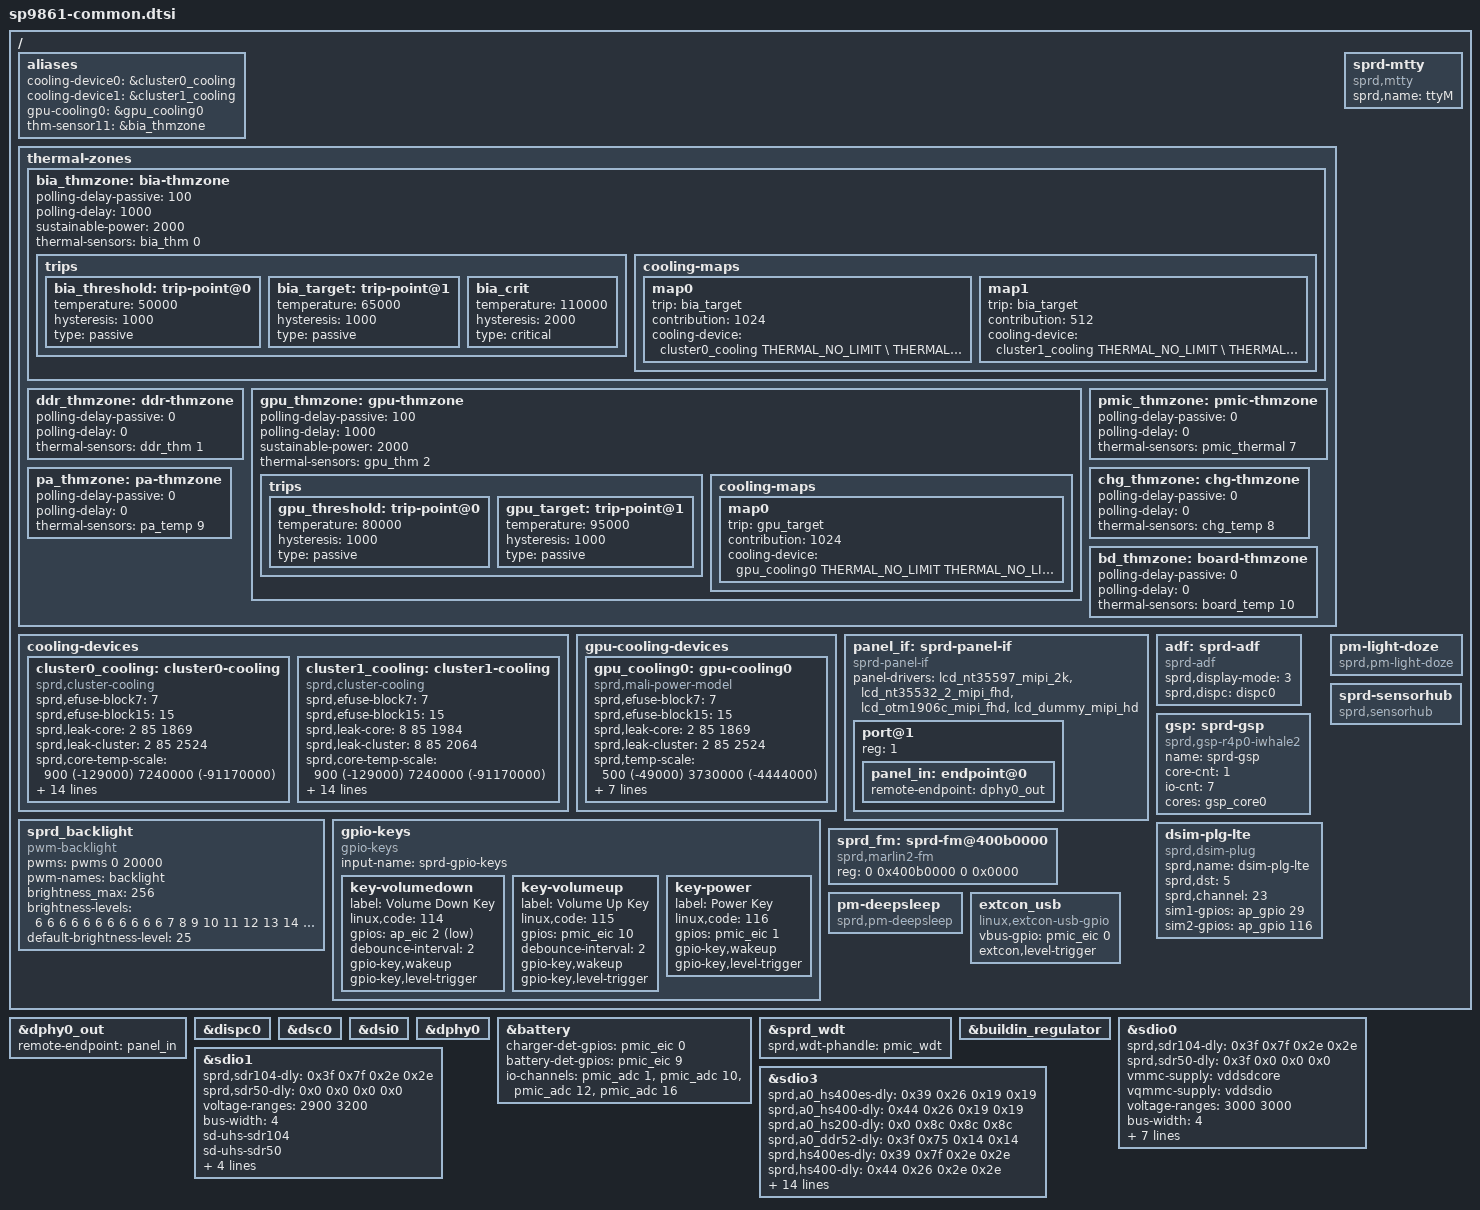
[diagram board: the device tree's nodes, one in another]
/*
 * Spreadtrum SP98x0 board common DTS file
 *
 * Copyright (C) 2016, Spreadtrum Communications Inc.
 *
 * This file is licensed under a dual GPLv2 or X11 license.
 */

#include "lcd/lcd_nt35532_2_mipi.dtsi"
#include "lcd/lcd_nt35597_mipi_2k.dtsi"
#include "lcd/lcd_otm1906c_mipi.dtsi"
#include "lcd/lcd_dummy_mipi.dtsi"
#include "sc2731.dtsi"
#include "sprd-battery.dtsi"
#include <dt-bindings/thermal/thermal.h>

/ {
	aliases {
		cooling-device0 = &cluster0_cooling;
		cooling-device1 = &cluster1_cooling;
		gpu-cooling0 = &gpu_cooling0;
		thm-sensor11 = &bia_thmzone;
	};

	thermal-zones {

		bia_thmzone: bia-thmzone {
			polling-delay-passive = <100>;
			polling-delay = <1000>;
			sustainable-power = <2000>;
			thermal-sensors = <&bia_thm  0>;
			trips {
				bia_threshold: trip-point@0 {
					temperature = <50000>;
					hysteresis = <1000>;
					type = "passive";
				};
				bia_target: trip-point@1 {
					temperature = <65000>;
					hysteresis = <1000>;
					type = "passive";
				};
				bia_crit: bia_crit {
					temperature = <110000>;
					hysteresis = <2000>;
					type = "critical";
				};
			};
			cooling-maps {
				map0 {
					trip = <&bia_target>;
					contribution = <1024>;
					cooling-device =
					<&cluster0_cooling THERMAL_NO_LIMIT \
					THERMAL_NO_LIMIT>;
				};
				map1 {
					trip = <&bia_target>;
					contribution = <512>;
					cooling-device =
					<&cluster1_cooling THERMAL_NO_LIMIT \
					THERMAL_NO_LIMIT>;
				};
			};
		};

		ddr_thmzone: ddr-thmzone {
			polling-delay-passive = <0>;
			polling-delay = <0>;
			thermal-sensors = <&ddr_thm  1>;
		};

		gpu_thmzone: gpu-thmzone {
			polling-delay-passive = <100>;
			polling-delay = <1000>;
			sustainable-power = <2000>;
			thermal-sensors = <&gpu_thm  2>;
			trips {
				gpu_threshold: trip-point@0 {
					temperature = <80000>;
					hysteresis = <1000>;
					type = "passive";
				};
				gpu_target: trip-point@1 {
					temperature = <95000>;
					hysteresis = <1000>;
					type = "passive";
				};
			};
			cooling-maps {
				map0 {
					trip = <&gpu_target>;
					contribution = <1024>;
					cooling-device =
					<&gpu_cooling0
						THERMAL_NO_LIMIT
						THERMAL_NO_LIMIT>;
				};
			};
		};

		pmic_thmzone: pmic-thmzone {
			polling-delay-passive = <0>;
			polling-delay = <0>;
			thermal-sensors = <&pmic_thermal 7>;
		};

		chg_thmzone: chg-thmzone {
			polling-delay-passive = <0>;
			polling-delay = <0>;
			thermal-sensors = <&chg_temp  8>;
		};

		pa_thmzone: pa-thmzone {
			polling-delay-passive = <0>;
			polling-delay = <0>;
			thermal-sensors = <&pa_temp  9>;
		};

		bd_thmzone: board-thmzone {
			polling-delay-passive = <0>;
			polling-delay = <0>;
			thermal-sensors = <&board_temp  10>;
		};
	};


	cooling-devices {
		cluster0_cooling: cluster0-cooling {
			compatible = "sprd,cluster-cooling";
			#cooling-cells = <2>; /* min followed by max */
			sprd,efuse-block7 = <7>;
			sprd,efuse-block15 = <15>;
			/* core_leak =                             */
			/*(LIT_LEAK[4:0]+1) x 2mA x 0.85V x 18.69% */
			sprd,leak-core = <2 85 1869>;
			/* cluster_leak =                           */
			/* (LIT_LEAK[4:0]+1) x 2mA x 0.85V x 25.24% */
			sprd,leak-cluster = <2 85 2524>;
			/*core Tscale = aT^3 + bT^2 + cT +di   */
			sprd,core-temp-scale =
			/* a*10^7   b*10^7      c*10^7     d*10^7 */
			<  900      (-129000)   7240000    (-91170000)>;
			/*core Vscale = eV^3 + fV^2 + gV + h */
			sprd,core-voltage-scale =
			/* e*10^2   f*10^2     g*10^2  h*10^2*/
			<  3401     (-8911)    7998    (-2351)>;
			/*cluster Tscale = aT^3 + bT^2 + cT +di   */
			sprd,cluster-temp-scale =
			/* a*10^7   b*10^7      c*10^7     d*10^7 */
			<  400      (-13000)   1940000    265070000>;
			/*cluster Vscale = eV^3 + fV^2 + gV + h */
			sprd,cluster-voltage-scale =
			/* e*10^2   f*10^2     g*10^2  h*10^2*/
			<  (-994)     4474     (-2848)    1799>;
			sprd,efuse-switch = <0>;
			sprd,hotplug-period = <10>;
			sprd,min-cpufreq = <936000>;
			sprd,min-cpunum = <3>;
			sprd,core-base = <38>;
			sprd,cluster-base = <3>;
			sprd,dynamic-core =
			/*Pdynperghz*10    Freq     Vbase  */
			< 3312           1000     1200>;
			sprd,dynamic-cluster =
			/*Pdynperghz*10    Freq     Vbase  */
			< 460           1000     1200>;
		};
		cluster1_cooling: cluster1-cooling {
			compatible = "sprd,cluster-cooling";
			#cooling-cells = <2>; /* min followed by max */
			sprd,efuse-block7 = <7>;
			sprd,efuse-block15 = <15>;
			/* core_leak =                             */
			/*(LIT_LEAK[4:0]+1) x 2mA x 0.85V x 18.69% */
			sprd,leak-core = <8 85 1984>;
			/* cluster_leak =                           */
			/* (LIT_LEAK[4:0]+1) x 2mA x 0.85V x 25.24% */
			sprd,leak-cluster = <8 85 2064>;
			/*core Tscale = aT^3 + bT^2 + cT +d  */
			sprd,core-temp-scale =
			/* a*10^7   b*10^7	c*10^7	   d*10^7*/
			<  900      (-129000)   7240000    (-91170000)>;
			/* core  Vscale = eV^3 + fV^2 + gV + h */
			sprd,core-voltage-scale =
			/* e*10^2  f*10^2     g*10^2  h*10^2*/
			<  3401    (-8911)    7998    (-2351)>;
			/*cluster Tscale = aT^3 + bT^2 + cT +di   */
			sprd,cluster-temp-scale =
			/* a*10^7   b*10^7      c*10^7     d*10^7 */
			<  400      (-13000)   1940000    265070000>;
			/*cluster Vscale = eV^3 + fV^2 + gV + h */
			sprd,cluster-voltage-scale =
			/* e*10^2   f*10^2     g*10^2  h*10^2*/
			<  (-994)     4474     (-2848)    1799>;
			sprd,efuse-switch = <0>;
			sprd,hotplug-period = <10>;
			sprd,min-cpufreq = <624000>;
			sprd,min-cpunum = <0>;
			sprd,core-base = <38>;
			sprd,cluster-base = <3>;
			sprd,dynamic-core =
			/* Pdynperghz*10    Freq     Vbase */
			<  3312          1000     1200>;
			sprd,dynamic-cluster =
			/* Pdynperghz*10    Freq     Vbase */
			<  460           1000     1200>;
		};
	};

	gpu-cooling-devices {
		gpu_cooling0: gpu-cooling0 {
			compatible = "sprd,mali-power-model";
			#cooling-cells = <2>;
			sprd,efuse-block7 = <7>;
			sprd,efuse-block15 = <15>;
			/* core_leak =                             */
			/*(LIT_LEAK[4:0]+1) x 2mA x 0.85V x 18.69% */
			sprd,leak-core = <2 85 1869>;
			/* cluster_leak =                           */
			/* (LIT_LEAK[4:0]+1) x 2mA x 0.85V x 25.24% */
			sprd,leak-cluster = <2 85 2524>;
			/*Tscale = aT^3 + bT^2 + cT +di   */
			sprd,temp-scale =
			/* a*10^7   b*10^7      c*10^7     d*10^7 */
			<  500     (-49000)   3730000    (-4444000)>;
			/*Vscale = eV^3 + fV^2 + gV + h */
			sprd,voltage-scale =
			/* e*10^2   f*10^2     g*10^2  h*10^2*/
			<  15623     (-42221)    40104    (-12970)>;
			sprd,hotplug-period = <0>;
			sprd,core-base = <68>;
			sprd,cluster-base = <68>;
			sprd,dynamic-core =
			/*Pdynperghz    Freq     Vbase  */
			< 2640           768     1050>;
			sprd,dynamic-cluster =
			/*Pdynperghz    Freq     Vbase  */
			< 1933           768     1050>;
		};
	};

	panel_if: sprd-panel-if {
		compatible = "sprd-panel-if";
		#address-cells = <1>;
		#size-cells = <0>;
		panel-drivers = <
			&lcd_nt35597_mipi_2k
			&lcd_nt35532_2_mipi_fhd
			&lcd_otm1906c_mipi_fhd
			&lcd_dummy_mipi_hd
		>;

		/* input port */
		port@1 {
		/* WARNING: the reg property must be 1 ! */
			reg = <1>;
			panel_in: endpoint@0 {
				remote-endpoint = <&dphy0_out>;
			};
		};
	};

	adf: sprd-adf {
		compatible = "sprd-adf";
		status = "okay";
		sprd,display-mode = <3>;
		sprd,dispc = <&dispc0>;
	};

	gsp: sprd-gsp {
		 compatible = "sprd,gsp-r4p0-iwhale2";
		 name = "sprd-gsp";
		 core-cnt = <1>;
		 io-cnt = <7>;
		 cores = <&gsp_core0>;
	};

	sprd_backlight: sprd_backlight {
		compatible = "pwm-backlight";
		pwms = <&pwms 0 20000>;
		pwm-names = "backlight";
		brightness_max = <256>;
		brightness-levels=<
						  6   6   6   6
			  6   6   6   6   6   6   6   7   8   9
			 10  11  12  13  14  15  16  17  18  19
			 20  21  22  23  24  25  26  27  28  29
			 30  31  32  33  34  35  36  37  38  39
			 40  41  42  43  44  45  46  47  48  49
			 50  51  52  53  54  55  56  57  58  59
			 60  61  62  63  64  65  66  67  68  69
			 70  71  72  73  74  75  76  77  78  79
			 80  81  82  83  84  85  86  87  88  89
			 90  91  92  93  94  95  96  97  98  99
			100 101 102 103 104 105 106 107 108 109
			110 111 112 113 114 115 116 117 118 119
			120 121 122 123 124 125 126 127 128 129
			130 131 132 133 134 135 136 137 138 139
			140 141 142 143 144 145 146 147 148 149
			150 151 152 153 154 155 156 157 158 159
			160 161 162 163 164 165 166 167 168 169
			170 171 172 173 174 175 176 177 178 179
			180 181 182 183 184 185 186 187 188 189
			190 191 192 193 194 195 196 197 198 199
			200 201 202 203 204 205 206 207 208 209
			210 211 212 213 214 215 216 217 218 219
			220 221 222 223 224 225 226 227 228 229
			230 231 232 233 234 235 236 237 238 239
			240 241 242 243 244 245 246 247 248 249
			250 251
			>;
		default-brightness-level = <25>;
	};
	gpio-keys {
		compatible = "gpio-keys";
		input-name = "sprd-gpio-keys";
		status = "okay";

		key-volumedown {
			label = "Volume Down Key";
			linux,code = <114>;
			gpios = <&ap_eic 2 1>;
			debounce-interval = <2>;
			gpio-key,wakeup;
			gpio-key,level-trigger;
		};

		key-volumeup {
			label = "Volume Up Key";
			linux,code = <115>;
			gpios = <&pmic_eic 10 0>;
			debounce-interval = <2>;
			gpio-key,wakeup;
			gpio-key,level-trigger;
		};

		key-power {
			label = "Power Key";
			linux,code = <116>;
			gpios = <&pmic_eic 1 0>;
			gpio-key,wakeup;
			gpio-key,level-trigger;
		};

	};

	dsim-plg-lte {
		compatible = "sprd,dsim-plug";
		sprd,name = "dsim-plg-lte";
		sprd,dst = <5>;
		sprd,channel = <23>;
		sim1-gpios = <&ap_gpio 29 0>;
		sim2-gpios = <&ap_gpio 116 0>;
	};

	sprd-mtty {
		compatible = "sprd,mtty";
		sprd,name = "ttyM";
	};

	sprd_fm: sprd-fm@400b0000{
		compatible  = "sprd,marlin2-fm";
		reg = <0 0x400b0000 0 0x0000>;
	};

	pm-light-doze {
		compatible = "sprd,pm-light-doze";
	};

	pm-deepsleep {
		compatible = "sprd,pm-deepsleep";
	};

	sprd-sensorhub {
		compatible = "sprd,sensorhub";
	};

	extcon_usb: extcon_usb {
		compatible = "linux,extcon-usb-gpio";
		vbus-gpio = <&pmic_eic 0 0>;
		/* id-gpio = <&ap_eic 7 0>; */
		extcon,level-trigger;
	};
};

&dphy0_out {
	remote-endpoint = <&panel_in>;
};

&dispc0 {
	status = "okay";
};

&dsc0 {
	status = "okay";
};

&dsi0 {
	status = "okay";
};

&dphy0 {
	status = "okay";
};

&battery {
	charger-det-gpios = <&pmic_eic 0 0>;
	battery-det-gpios = <&pmic_eic 9 0>;
	io-channels = <&pmic_adc 1>,<&pmic_adc 10>,
			<&pmic_adc 12>,<&pmic_adc 16>;
	io-channel-names = "adc_temp","adc_vbat",
			"adc_vchg","adc_isense";
	status = "okay";
};

&sprd_wdt {
	sprd,wdt-phandle = <&pmic_wdt>;
};

&buildin_regulator{
	status = "okay";
};

&sdio0 {
	sprd,sdr104-dly = <0x3f 0x7f 0x2e 0x2e>;
	sprd,sdr50-dly = <0x3f 0x0 0x0 0x0>;
	vmmc-supply = <&vddsdcore>;
	vqmmc-supply = <&vddsdio>;
	voltage-ranges = <3000 3000>;
	bus-width = <4>;
	sd-uhs-sdr104;
	sd-uhs-sdr50;
	sprd,name = "sdio_sd";
	no-sdio;
	no-mmc;
	pinctrl-names = "sd0_ms_0","sd0_ms_1";
	pinctrl-0 = <&vio_sd0_ms_0>;
	pinctrl-1 = <&vio_sd0_ms_1>;
	status = "okay";
};

&sdio1 {
	sprd,sdr104-dly = <0x3f 0x7f 0x2e 0x2e>;
	sprd,sdr50-dly = <0x0 0x0 0x0 0x0>;
	voltage-ranges = <2900 3200>;
	bus-width = <4>;
	sd-uhs-sdr104;
	sd-uhs-sdr50;
	sprd,name = "sdio_wifi";
	no-sd;
	no-mmc;
	keep-power-in-suspend;
	status = "okay";
};

&sdio3 {
	sprd,a0_hs400es-dly = <0x39 0x26 0x19 0x19>;
	sprd,a0_hs400-dly = <0x44 0x26 0x19 0x19>;
	sprd,a0_hs200-dly = <0x0 0x8c 0x8c 0x8c>;
	sprd,a0_ddr52-dly = <0x3f 0x75 0x14 0x14>;
};

&sdio3 {
	sprd,hs400es-dly = <0x39 0x7f 0x2e 0x2e>;
	sprd,hs400-dly = <0x44 0x26 0x2e 0x2e>;
	sprd,hs200-dly = <0x0 0x8c 0x8c 0x8c>;
	sprd,ddr52-dly = <0x3f 0x75 0x14 0x14>;
	vmmc-supply = <&vddemmccore>;
	voltage-ranges = <3000 3000>;
	bus-width = <8>;
	non-removable;
	cap-mmc-hw-reset;
	mmc-hs400-enhanced-strobe;
	mmc-hs400-1_8v;
	mmc-hs200-1_8v;
	mmc-ddr-1_8v;
	sprd,name = "sdio_emmc";
	no-sdio;
	no-sd;
	status = "okay";
};
